# Nimitz register map
File version: 1.0
ARM 32-bit Cortex-M4 Microcontroller
Registers are 32-bit, read-write, reset 0x0 unless marked. A register's access mark holds for its fields unless they carry their own. Offsets are from the block's base; lines under a group give offsets from that group; [hi:lo] are bit positions; {n}, {i} and the like mark numbered series; 'fields as' and 'values as' point back to an identical list; <NAME> marks a mode.

## Memory map
0x40004000 SPIX size 0x1000 — SPI XIP Interface
0x4000D000 SPIB size 0x1000 — SPIB AHB-to-SPI Bridge
0x4000E000 OWM size 0x1000 — 1-Wire Master Interface

## SPIX — SPI XIP Interface
Base 0x40004000
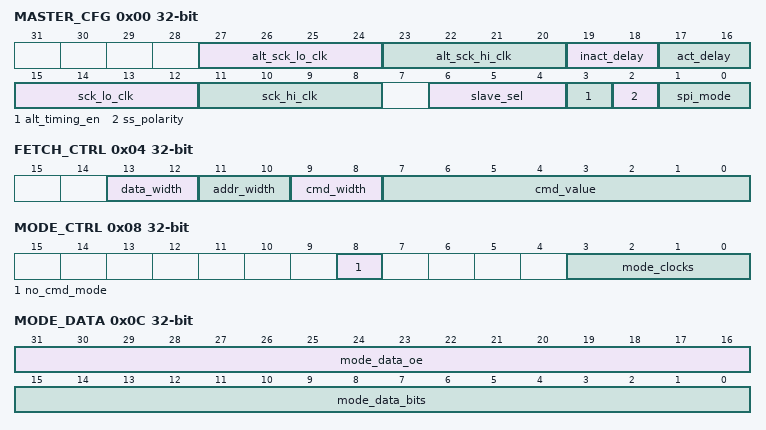
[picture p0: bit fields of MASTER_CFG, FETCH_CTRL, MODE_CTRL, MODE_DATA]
0x00 MASTER_CFG — SPIX Master Configuration
  [27:24] alt_sck_lo_clk — Alt SCK Low Clocks
  [23:20] alt_sck_hi_clk — Alt SCK High Clocks
  [19:18] inact_delay — SS Inactive Timing
  [17:16] act_delay — SS Active Timing
  [15:12] sck_lo_clk — SCK Low Clocks
  [11:8] sck_hi_clk — SCK High Clocks
  [6:4] slave_sel — SPIX Slave Select
  [3] alt_timing_en — Alternate Timing Mode Enable
  [2] ss_polarity — SPIX Slave Select Polarity
  [1:0] spi_mode — SPIX Mode
0x04 FETCH_CTRL — SPIX Fetch Control
  [13:12] data_width
  [11:10] addr_width — Address Width
  [9:8] cmd_width — Command Width
  [7:0] cmd_value — Command Value
0x08 MODE_CTRL — SPIX Mode Control
  [8] no_cmd_mode — No Command Mode
  [3:0] mode_clocks
0x0C MODE_DATA — SPIX Mode Data
  [31:16] mode_data_oe — Mode Output Enable
  [15:0] mode_data_bits — Mode Data

## SPIB — SPIB AHB-to-SPI Bridge
Base 0x4000D000
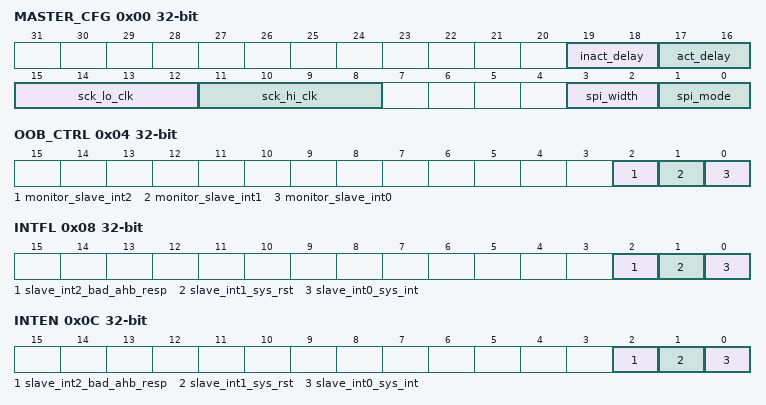
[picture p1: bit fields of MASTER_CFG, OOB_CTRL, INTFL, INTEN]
0x00 MASTER_CFG — SPIB Master Configuration
  [19:18] inact_delay — SS Inactive Timing
  [17:16] act_delay — SS Active Timing
  [15:12] sck_lo_clk — SCK Low Clocks
  [11:8] sck_hi_clk — SCK High Clocks
  [3:2] spi_width — SPIB Width
  [1:0] spi_mode — SPIB Mode
0x04 OOB_CTRL — SPIB OOB Control
  [2] monitor_slave_int2 — Slave Bad AHB Response Monitor Enable
  [1] monitor_slave_int1 — Slave System Rst Monitor Enable
  [0] monitor_slave_int0 — Slave System Int Monitor Enable
0x08 INTFL — SPIB Interrupt Flags
  [2] slave_int2_bad_ahb_resp write-1-clears — Slave Bad AHB Response Detected
  [1] slave_int1_sys_rst write-1-clears — Slave System Reset Detected
  [0] slave_int0_sys_int write-1-clears — Slave System Int Detected
0x0C INTEN — SPIB Interrupt Enables
  [2] slave_int2_bad_ahb_resp — Slave Bad AHB Response Detected Interrupt Enable
  [1] slave_int1_sys_rst — Slave System Reset Detected Interrupt Enable
  [0] slave_int0_sys_int — Slave System Int Detected Interrupt Enable
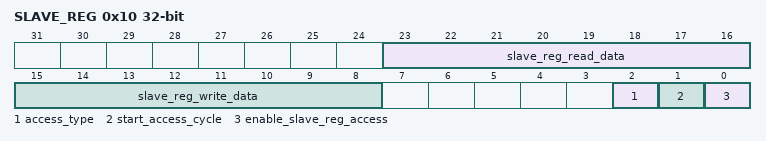
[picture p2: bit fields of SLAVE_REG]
0x10 SLAVE_REG — SPIB Slave Register Access
  [23:16] slave_reg_read_data ro — SPIB Slave Register Read Data
  [15:8] slave_reg_write_data — SPIB Slave Register Write Data
  [2] access_type — SPIB Slave Register Access Mode
  [1] start_access_cycle — Start SPIB Slave Register Access Cycle
  [0] enable_slave_reg_access — SPIB Slave Register Access Enable

## OWM — 1-Wire Master Interface
Base 0x4000E000
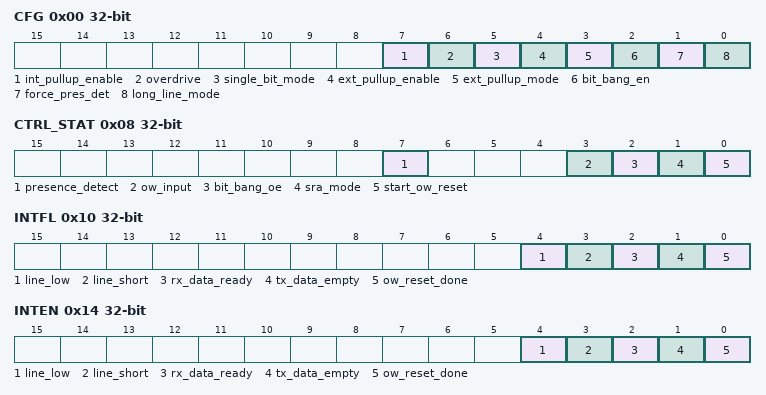
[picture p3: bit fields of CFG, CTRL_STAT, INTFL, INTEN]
0x00 CFG — 1-Wire Master Configuration
  [7] int_pullup_enable — Enable internal pullup.
  [6] overdrive — Enables overdrive speed for 1-Wire operations.
  [5] single_bit_mode — Enable Single Bit TX/RX Mode
  [4] ext_pullup_enable — Enable External Pullup
  [3] ext_pullup_mode — Provide an extra output to control an external pullup.
  [2] bit_bang_en — Bit Bang Enable
  [1] force_pres_det — Force Line During Presence Detect
  [0] long_line_mode
0x04 CLK_DIV_1US — 1-Wire Master Clock Divisor
  [7:0] divisor — Clock Divisor for 1MHz
0x08 CTRL_STAT — 1-Wire Master Control/Status
  [7] presence_detect — Presence Pulse Detected
  [3] ow_input ro — OW Input State
  [2] bit_bang_oe — Bit Bang Output Enable
  [1] sra_mode
  [0] start_ow_reset
0x0C DATA — 1-Wire Master Data Buffer
  [7:0] tx_rx — Tx/Rx Buffer
0x10 INTFL — 1-Wire Master Interrupt Flags
  [4] line_low — OW Line Low Detected Interrupt Flag
  [3] line_short — OW Line Short Detected Interrupt Flag
  [2] rx_data_ready — Rx Data Ready Interrupt Flag
  [1] tx_data_empty — Tx Data Empty Interrupt Flag
  [0] ow_reset_done — OW Reset Sequence Completed
0x14 INTEN — 1-Wire Master Interrupt Enables
  [4] line_low write-1-clears — OW Line Low Detected Interrupt Enable
  [3] line_short write-1-clears — OW Line Short Detected Interrupt Enable
  [2] rx_data_ready write-1-clears — Rx Data Ready Interrupt Enable
  [1] tx_data_empty write-1-clears — Tx Data Empty Interrupt Enable
  [0] ow_reset_done write-1-clears — OW Reset Sequence Completed
